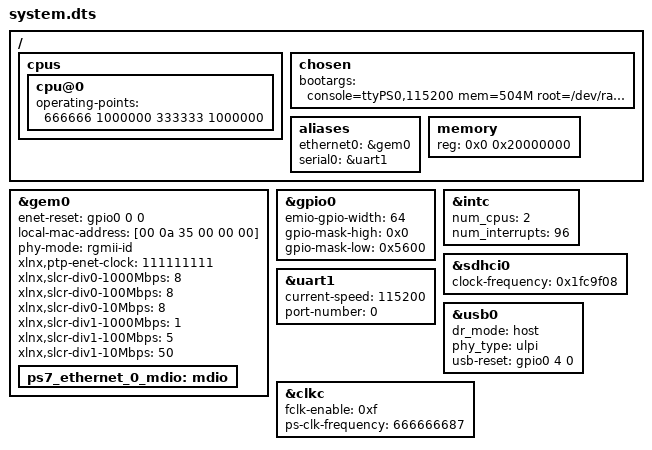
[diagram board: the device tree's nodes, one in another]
/*
 * CAUTION: This file is automatically generated by Xilinx.
 * Version:  
 * Today is: Fri Apr 22 22:12:07 2016
*/


/dts-v1/;
/include/ "zynq-7000.dtsi"
/include/ "pl.dtsi"
/ {
	cpus {
		cpu@0 {
			operating-points = <666666 1000000 333333 1000000>;
		};
	};
	chosen {
		bootargs = "console=ttyPS0,115200 mem=504M root=/dev/ram rw initrd=0x800000,8M earlyprintk rootfstype=ext4 rootwait devtmpfs.mount=0";
	};
	aliases {
		ethernet0 = &gem0;
		serial0 = &uart1;
	};
	memory {
		device_type = "memory";
		reg = <0x0 0x20000000>;
	};
};
&gem0 {
	enet-reset = <&gpio0 0 0>;
	local-mac-address = [00 0a 35 00 00 00];
	phy-mode = "rgmii-id";
	status = "okay";
	xlnx,ptp-enet-clock = <111111111>;
	xlnx,slcr-div0-1000Mbps = <8>;
	xlnx,slcr-div0-100Mbps = <8>;
	xlnx,slcr-div0-10Mbps = <8>;
	xlnx,slcr-div1-1000Mbps = <1>;
	xlnx,slcr-div1-100Mbps = <5>;
	xlnx,slcr-div1-10Mbps = <50>;
	ps7_ethernet_0_mdio: mdio {
		#address-cells = <1>;
		#size-cells = <0>;
	};
};
&gpio0 {
	emio-gpio-width = <64>;
	gpio-mask-high = <0x0>;
	gpio-mask-low = <0x5600>;
};
&intc {
	num_cpus = <2>;
	num_interrupts = <96>;
};
&sdhci0 {
	clock-frequency = <0x1fc9f08>;
	status = "okay";
};
&uart1 {
	current-speed = <115200>;
	device_type = "serial";
	port-number = <0>;
	status = "okay";
};
&usb0 {
	dr_mode = "host";
	phy_type = "ulpi";
	status = "okay";
	usb-reset = <&gpio0 4 0>;
};
&clkc {
	fclk-enable = <0xf>;
	ps-clk-frequency = <666666687>;
};
